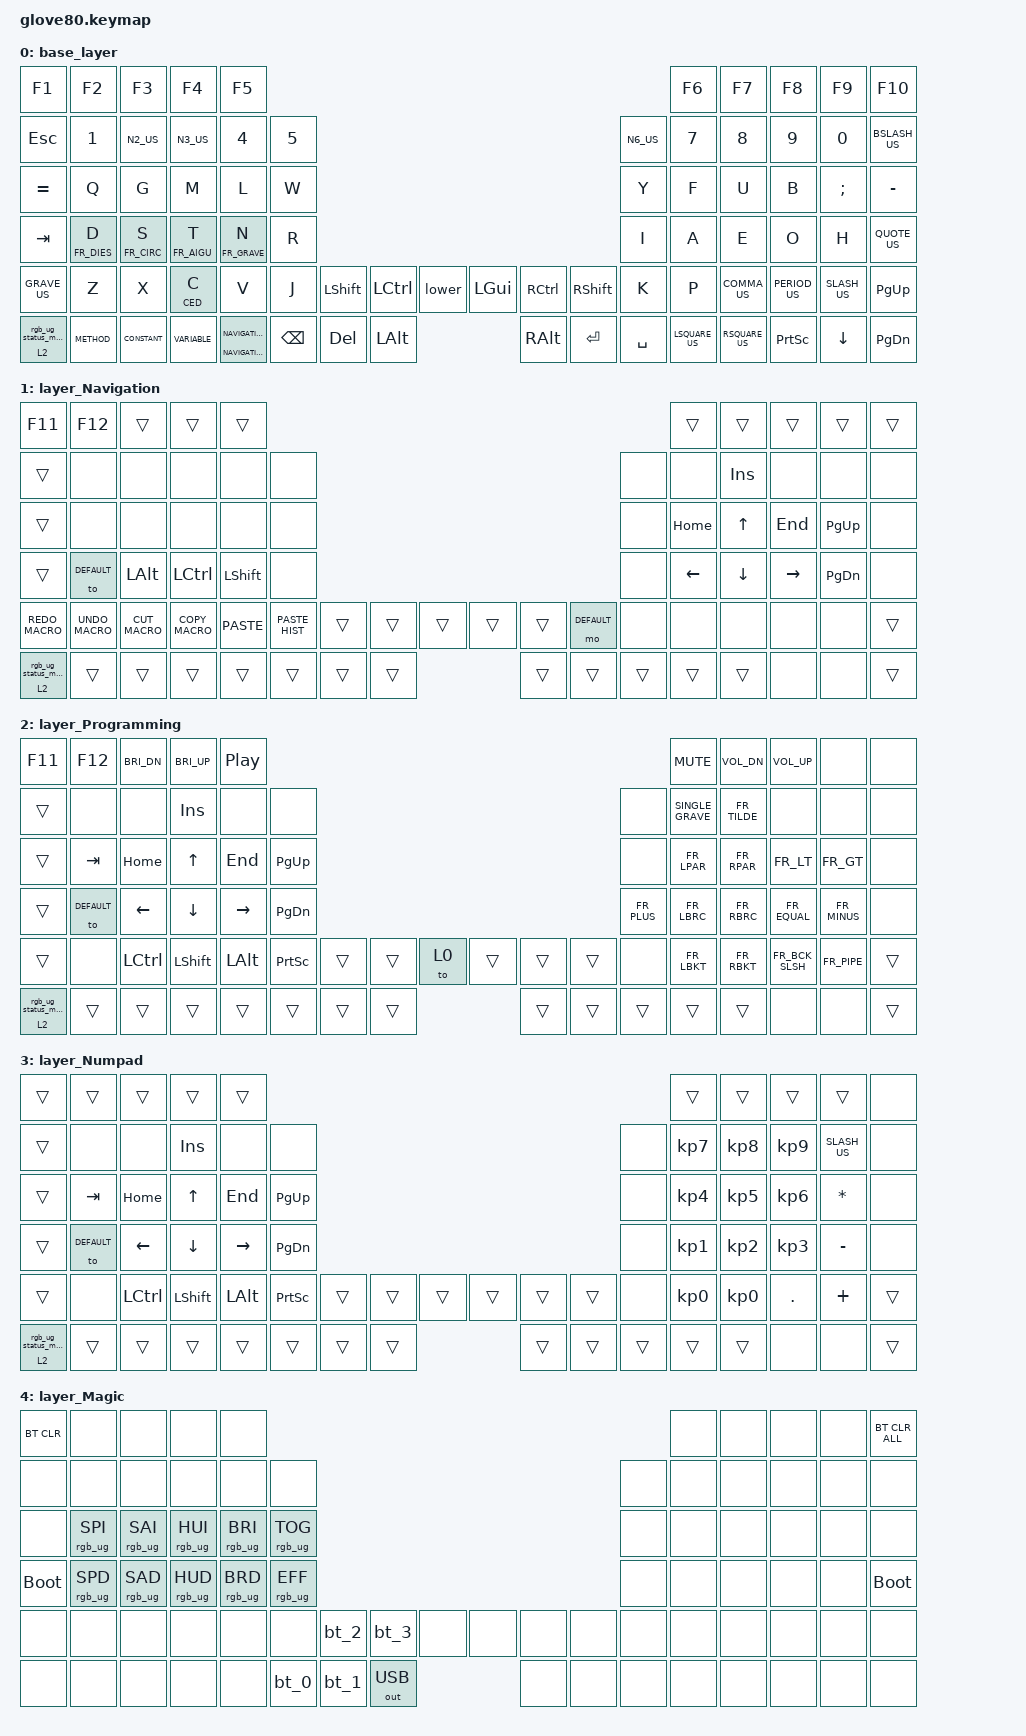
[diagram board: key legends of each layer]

/*
 * Copyright (c) 2020 The ZMK Contributors
 * Copyright (c) 2022 Innaworks Development Limited, trading as MoErgo
 *
 * SPDX-License-Identifier: MIT
 */


/* THIS FILE WAS GENERATED BY GLOVE80 LAYOUT EDITOR
 *
 * This file was generated automatically. You may or may not want to
 * edit it directly.
 */

#include <behaviors.dtsi>
/* Include all behaviour includes needed by system behaviors/macros */
#include <dt-bindings/zmk/outputs.h>

/* Include behaviour includes needed by key binds - automatically generated */
#include <dt-bindings/zmk/keys.h>
#include <dt-bindings/zmk/bt.h>
#include <dt-bindings/zmk/rgb.h>
#include <dt-bindings/zmk/outputs.h>
#include <dt-bindings/zmk/keyboards/keys_fr_cafr.h>

#define DEFAULT  0
#define NAVIGATION   1
#define SYMBOL   2
#define NUMPAD  3

#define VOWEL_A 42
#define VOWEL_E 43
#define VOWEL_I 41
#define VOWEL_O 44
#define VOWEL_U 31
#define AIGU_VOWELS VOWEL_E
#define GRAVE_VOWELS VOWEL_A VOWEL_E VOWEL_U
#define CIRC_VOWELS VOWEL_A VOWEL_E VOWEL_I VOWEL_O VOWEL_U
#define TREMA_VOWELS VOWEL_E VOWEL_I VOWEL_U


/ {
    /* Glove80 system behavior & macros */
    behaviors {
        // For the "layer" key, it'd nice to be able to use it as either a shift or a toggle.
        // Configure it as a tap dance, so the first tap (or hold) is a &mo and the second tap is a &to
        lower: tap_dance_0 {
            compatible = "zmk,behavior-tap-dance";
            label = "LAYER_TAP_DANCE";
            #binding-cells = <0>;
            tapping-term-ms = <200>;
            bindings = <&mo 1>, <&to 1>;
        };

        GRAVE_US: GRAVE_US {
            compatible = "zmk,behavior-mod-morph";
            label = "GRAVE_US";
            #binding-cells = <0>;
            bindings = <&SINGLE_GRAVE>, <&kp FR_TILDE>;
            mods = <(MOD_LSFT|MOD_RSFT)>;
        };

        N2_US: N2_US {
            compatible = "zmk,behavior-mod-morph";
            label = "N2_US";
            #binding-cells = <0>;
            bindings = <&kp N2>, <&kp FR_AT>;
            mods = <(MOD_LSFT|MOD_RSFT)>;
        };

        N3_US: N3_US {
            compatible = "zmk,behavior-mod-morph";
            label = "N3_US";
            #binding-cells = <0>;
            bindings = <&kp N3>, <&kp FR_HASH>;
            mods = <(MOD_LSFT|MOD_RSFT)>;
        };

        N6_US: N6_US {
            compatible = "zmk,behavior-mod-morph";
            label = "N6_US";
            #binding-cells = <0>;
            bindings = <&kp N6>, <&SINGLE_KARET>;
            mods = <(MOD_LSFT|MOD_RSFT)>;
        };

        LSQUARE_US: LSQUARE_US {
            compatible = "zmk,behavior-mod-morph";
            label = "LSQUARE_US";
            #binding-cells = <0>;
            bindings = <&kp FR_LBKT>, <&kp FR_LBRC>;
            mods = <(MOD_LSFT|MOD_RSFT)>;
        };

        RSQUARE_US: RSQUARE_US {
            compatible = "zmk,behavior-mod-morph";
            label = "RSQUARE_US";
            #binding-cells = <0>;
            bindings = <&kp FR_RBKT>, <&kp FR_RBRC>;
            mods = <(MOD_LSFT|MOD_RSFT)>;
        };

        BSLASH_US: BSLASH_US {
            compatible = "zmk,behavior-mod-morph";
            label = "BSLASH_US";
            #binding-cells = <0>;
            bindings = <&kp FR_BCK_SLSH>, <&kp FR_PIPE>;
            mods = <(MOD_LSFT|MOD_RSFT)>;
        };

        QUOTE_US: QUOTE_US {
            compatible = "zmk,behavior-mod-morph";
            label = "QUOTE_US";
            #binding-cells = <0>;
            bindings = <&kp FR_SINGLE_QUOTE>, <&kp FR_QUOTE>;
            mods = <(MOD_LSFT|MOD_RSFT)>;
        };

        COMMA_US: COMMA_US {
            compatible = "zmk,behavior-mod-morph";
            label = "COMMA_US";
            #binding-cells = <0>;
            bindings = <&kp FR_COMMA>, <&kp FR_LT>;
            mods = <(MOD_LSFT|MOD_RSFT)>;
        };

        PERIOD_US: PERIOD_US {
            compatible = "zmk,behavior-mod-morph";
            label = "PERIOD_US";
            #binding-cells = <0>;
            bindings = <&kp FR_DOT>, <&kp FR_GT>;
            mods = <(MOD_LSFT|MOD_RSFT)>;
        };

        SLASH_US: SLASH_US {
            compatible = "zmk,behavior-mod-morph";
            label = "SLASH_US";
            #binding-cells = <0>;
            bindings = <&kp FR_SLASH>, <&kp FR_QUES>;
            mods = <(MOD_LSFT|MOD_RSFT)>;
        };

        ACC_1: ACC_1 {
            compatible = "zmk,behavior-hold-tap";
            label = "ACCENT_1";
            #binding-cells = <2>;
            flavor = "balanced";
            tapping-term-ms = <175>;
            quick-tap-ms = <150>;
            global-quick-tap-ms = <150>;
            bindings = <&kp>, <&kp>;
            hold-trigger-key-positions = <GRAVE_VOWELS>;
            hold-trigger-on-release;
        };

        ACC_2: ACC_2 {
            compatible = "zmk,behavior-hold-tap";
            label = "ACCENT_2";
            #binding-cells = <2>;
            flavor = "balanced";
            tapping-term-ms = <175>;
            quick-tap-ms = <150>;
            global-quick-tap-ms = <150>;
            bindings = <&kp>, <&kp>;
            hold-trigger-key-positions = <AIGU_VOWELS>;
            hold-trigger-on-release;
        };

        ACC_3: ACC_3 {
            compatible = "zmk,behavior-hold-tap";
            label = "ACCENT_3";
            #binding-cells = <2>;
            flavor = "balanced";
            tapping-term-ms = <175>;
            quick-tap-ms = <150>;
            global-quick-tap-ms = <150>;
            bindings = <&kp>, <&kp>;
            hold-trigger-key-positions = <CIRC_VOWELS>;
            hold-trigger-on-release;
        };

        ACC_4: ACC_4 {
            compatible = "zmk,behavior-hold-tap";
            label = "ACCENT_4";
            #binding-cells = <2>;
            flavor = "balanced";
            tapping-term-ms = <175>;
            quick-tap-ms = <150>;
            global-quick-tap-ms = <150>;
            bindings = <&kp>, <&kp>;
            hold-trigger-key-positions = <TREMA_VOWELS>;
            hold-trigger-on-release;
        };

        TO_OR_MO: TO_OR_MO {
            compatible = "zmk,behavior-hold-tap";
            label = "TO_OR_MO";
            #binding-cells = <2>;
            flavor = "balanced";
            tapping-term-ms = <300>;
            bindings = <&mo>, <&to>;
            hold-trigger-on-release;
        };

        CED: CED {
            compatible = "zmk,behavior-hold-tap";
            label = "CED";
            #binding-cells = <2>;
            flavor = "balanced";
            tapping-term-ms = <175>;
            quick-tap-ms = <150>;
            global-quick-tap-ms = <150>;
            bindings = <&CAPITAL_CED_OR_NOT>, <&kp>;
            hold-trigger-key-positions = <49>;
            hold-trigger-on-release;
        };

        CAPITAL_CED_OR_NOT: CAPITAL_CED_OR_NOT {
            compatible = "zmk,behavior-mod-morph";
            label = "CAPITAL_CED_OR_NOT";
            #binding-cells = <0>;
            bindings = <&C_CEDILLE>, <&CAPITAL_C_CEDILLE>;
            mods = <(MOD_LSFT|MOD_RSFT)>;
        };
    };


    macros {
        rgb_ug_status_macro: rgb_ug_status_macro_0 {
            label = "RGB_UG_STATUS";
            compatible = "zmk,behavior-macro";
            #binding-cells = <0>;
            bindings
                = <&rgb_ug RGB_STATUS>;
        };

        SINGLE_KARET: SINGLE_KARET {
            label = "SINGLE_KARET";
            compatible = "zmk,behavior-macro";
            #binding-cells = <0>;
            wait-ms = <0>;
            tap-ms = <0>;
            bindings = <&macro_tap &kp FR_CIRC &kp FR_CIRC &kp BSPC>;
        };

        SINGLE_GRAVE: SINGLE_GRAVE {
            label = "SINGLE_GRAVE";
            compatible = "zmk,behavior-macro";
            #binding-cells = <0>;
            wait-ms = <0>;
            tap-ms = <0>;
            bindings = <&macro_tap &kp FR_GRAVE &kp FR_GRAVE &kp BSPC>;
        };

        C_CEDILLE: C_CEDILLE {
            label = "C_CEDILLE";
            compatible = "zmk,behavior-macro";
            #binding-cells = <0>;
            wait-ms = <0>;
            tap-ms = <0>;
            bindings = <&macro_tap &kp FR_CED &kp C>;
        };

        CAPITAL_C_CEDILLE: CAPITAL_C_CEDILLE {
            label = "CAPITAL_C_CEDILLE";
            compatible = "zmk,behavior-macro";
            #binding-cells = <0>;
            wait-ms = <0>;
            tap-ms = <0>;
            bindings =
                <&macro_tap &kp FR_CED>,
                <&macro_press &kp LSHFT>,
                <&macro_tap &kp C>,
                <&macro_release &kp LSHFT>;
        };

        COPY_MACRO: COPY_MACRO {
            label = "COPY_MACRO";
            compatible = "zmk,behavior-macro";
            #binding-cells = <0>;
            wait-ms = <0>;
            tap-ms = <0>;
            bindings =
                <&macro_press &kp LCTRL>,
                <&macro_tap &kp C>,
                <&macro_release &kp LCTRL>;
        };

        PASTE: PASTE {
            label = "PASTE";
            compatible = "zmk,behavior-macro";
            #binding-cells = <0>;
            wait-ms = <0>;
            tap-ms = <0>;
            bindings =
                <&macro_press &kp LCTRL>,
                <&macro_tap &kp V>,
                <&macro_release &kp LCTRL>;
        };

        CUT_MACRO: CUT_MACRO {
            label = "CUT_MACRO";
            compatible = "zmk,behavior-macro";
            #binding-cells = <0>;
            wait-ms = <0>;
            tap-ms = <0>;
            bindings =
                <&macro_press &kp LCTRL>,
                <&macro_tap &kp X>,
                <&macro_release &kp LCTRL>;
        };

        UNDO_MACRO: UNDO_MACRO {
            label = "UNDO_MACRO";
            compatible = "zmk,behavior-macro";
            #binding-cells = <0>;
            wait-ms = <0>;
            tap-ms = <0>;
            bindings =
                <&macro_press &kp LCTRL>,
                <&macro_tap &kp Z>,
                <&macro_release &kp LCTRL>;
        };

        REDO_MACRO: REDO_MACRO {
            label = "REDO_MACRO";
            compatible = "zmk,behavior-macro";
            #binding-cells = <0>;
            wait-ms = <0>;
            tap-ms = <0>;
            bindings =
                <&macro_press &kp LCTRL>,
                <&macro_press &kp LSHFT>,
                <&macro_tap &kp Z>,
                <&macro_release &kp LCTRL>,
                <&macro_release &kp LSHFT>;
        };

        PASTE_HIST: PASTE_HIST {
            label = "PASTE_HIST";
            compatible = "zmk,behavior-macro";
            #binding-cells = <0>;
            wait-ms = <0>;
            tap-ms = <0>;
            bindings =
                <&macro_press &kp LCTRL>,
                <&macro_press &kp LSHFT>,
                <&macro_tap &kp V>,
                <&macro_release &kp LCTRL>,
                <&macro_release &kp LSHFT>;
        };

        VARIABLE: VARIABLE {
            label = "VARIABLE";
            compatible = "zmk,behavior-macro";
            #binding-cells = <0>;
            wait-ms = <0>;
            tap-ms = <0>;
            bindings =
                <&macro_press &kp LCTRL>,
                <&macro_press &kp LALT>,
                <&macro_tap &kp V>,
                <&macro_release &kp LCTRL>,
                <&macro_release &kp LALT>;
        };

        CONSTANT: CONSTANT {
            label = "CONSTANT";
            compatible = "zmk,behavior-macro";
            #binding-cells = <0>;
            wait-ms = <0>;
            tap-ms = <0>;
            bindings =
                <&macro_press &kp LCTRL>,
                <&macro_press &kp LALT>,
                <&macro_tap &kp C>,
                <&macro_release &kp LCTRL>,
                <&macro_release &kp LALT>;
        };

        METHOD: METHOD {
            label = "METHOD";
            compatible = "zmk,behavior-macro";
            #binding-cells = <0>;
            wait-ms = <0>;
            tap-ms = <0>;
            bindings =
                <&macro_press &kp LCTRL>,
                <&macro_press &kp LALT>,
                <&macro_tap &kp M>,
                <&macro_release &kp LCTRL>,
                <&macro_release &kp LALT>;
        };

        bt_0: bt_profile_macro_0 {
            label = "BT_0";
            compatible = "zmk,behavior-macro";
            #binding-cells = <0>;
            bindings
                = <&out OUT_BLE>,
                  <&bt BT_SEL 0>;
        };

        bt_1: bt_profile_macro_1 {
            label = "BT_1";
            compatible = "zmk,behavior-macro";
            #binding-cells = <0>;
            bindings
                = <&out OUT_BLE>,
                  <&bt BT_SEL 1>;
        };

        bt_2: bt_profile_macro_2 {
            label = "BT_2";
            compatible = "zmk,behavior-macro";
            #binding-cells = <0>;
            bindings
                = <&out OUT_BLE>,
                  <&bt BT_SEL 2>;
        };

        bt_3: bt_profile_macro_3 {
            label = "BT_3";
            compatible = "zmk,behavior-macro";
            #binding-cells = <0>;
            bindings
                = <&out OUT_BLE>,
                  <&bt BT_SEL 3>;
        };
    };

    magic: magic_hold_tap {
        compatible = "zmk,behavior-hold-tap";
        label = "MAGIC_HOLD_TAP";
        #binding-cells = <2>;
        flavor = "tap-preferred";
        tapping-term-ms = <200>;
        bindings = <&mo>, <&rgb_ug_status_macro>;
    };

    /* Custom Defined Behaviors */


    /* Automatically generated keymap */
    keymap {
        compatible = "zmk,keymap";


        base_layer {
            bindings = <
     &kp F1    &kp F2             &kp F3              &kp F4                    &kp F5                                                                                     &kp F6  &kp F7       &kp F8       &kp F9      &kp F10
    &kp ESC    &kp N1             &N2_US              &N3_US                    &kp N4                         &kp N5                                                                  &N6_US  &kp N7       &kp N8       &kp N9       &kp N0   &BSLASH_US
  &kp EQUAL     &kp Q              &kp G               &kp M                     &kp L                          &kp W                                                                   &kp Y   &kp F        &kp U        &kp B     &kp SEMI    &kp MINUS
    &kp TAB    &ACC_4 FR_DIES D   &ACC_3 FR_CIRC S    &ACC_2 FR_AIGU T          &ACC_1 FR_GRAVE N               &kp R                                                                   &kp I   &kp A        &kp E        &kp O        &kp H    &QUOTE_US
  &GRAVE_US     &kp Z              &kp X                &CED C            &kp V                          &kp J  &kp LSHFT  &kp LCTRL    &lower  &kp LGUI  &kp RCTRL  &kp RSHFT   &kp K   &kp P    &COMMA_US   &PERIOD_US    &SLASH_US    &kp PG_UP
 &magic 2 0   &METHOD          &CONSTANT           &VARIABLE                 &TO_OR_MO NAVIGATION NAVIGATION            &kp BSPC    &kp DEL  &kp LALT  &kp RALT    &kp RET  &kp SPACE     &LSQUARE_US  &RSQUARE_US    &kp PSCRN     &kp DOWN    &kp PG_DN
            >;
        };

        layer_Navigation {
            bindings = <
    &kp F11      &kp F12      &trans       &trans     &trans                                                                               &trans     &trans     &trans      &trans  &trans
     &trans        &none       &none        &none      &none        &none                                                        &none      &none    &kp INS      &none       &none   &none
     &trans      &none         &none        &none      &none        &none                                                        &none   &kp HOME     &kp UP    &kp END   &kp PG_UP   &none
     &trans  &to DEFAULT    &kp LALT    &kp LCTRL  &kp LSHFT        &none                                                        &none   &kp LEFT   &kp DOWN  &kp RIGHT   &kp PG_DN   &none
&REDO_MACRO  &UNDO_MACRO  &CUT_MACRO  &COPY_MACRO     &PASTE  &PASTE_HIST  &trans  &trans  &trans  &trans  &trans  &mo DEFAULT   &none      &none      &none      &none       &none  &trans
 &magic 2 0       &trans      &trans       &trans     &trans               &trans  &trans  &trans  &trans  &trans  &trans       &trans     &trans      &none      &none      &trans
            >;
        };

        layer_Programming {
            bindings = <
    &kp F11      &kp F12    &kp C_BRI_DN    &kp C_BRI_UP         &kp C_PP                                                                                 &kp C_MUTE     &kp C_VOL_DN     &kp C_VOL_UP         &none   &none
     &trans        &none           &none         &kp INS            &none      &none                                                         &none     &SINGLE_GRAVE     &kp FR_TILDE            &none         &none   &none
     &trans      &kp TAB        &kp HOME    &kp UP_ARROW          &kp END  &kp PG_UP                                                         &none       &kp FR_LPAR      &kp FR_RPAR        &kp FR_LT     &kp FR_GT   &none
     &trans  &to DEFAULT  &kp LEFT_ARROW  &kp DOWN_ARROW  &kp RIGHT_ARROW  &kp PG_DN                                                   &kp FR_PLUS       &kp FR_LBRC      &kp FR_RBRC     &kp FR_EQUAL  &kp FR_MINUS   &none
     &trans        &none       &kp LCTRL       &kp LSHFT         &kp LALT  &kp PSCRN  &trans  &trans   &to 0  &trans  &trans  &trans         &none       &kp FR_LBKT      &kp FR_RBKT  &kp FR_BCK_SLSH   &kp FR_PIPE  &trans
 &magic 2 0       &trans          &trans          &trans           &trans             &trans  &trans  &trans  &trans  &trans  &trans                          &trans           &trans            &none         &none  &trans
            >;
        };

        layer_Numpad {
            bindings = <
     &trans       &trans     &trans     &trans     &trans                                                                        &trans     &trans     &trans     &trans   &none
     &trans        &none      &none    &kp INS      &none      &none                                                   &none  &kp KP_N7  &kp KP_N8  &kp KP_N9  &SLASH_US   &none
     &trans      &kp TAB   &kp HOME     &kp UP    &kp END  &kp PG_UP                                                   &none  &kp KP_N4  &kp KP_N5  &kp KP_N6   &kp STAR   &none
     &trans  &to DEFAULT   &kp LEFT   &kp DOWN  &kp RIGHT  &kp PG_DN                                                   &none  &kp KP_N1  &kp KP_N2  &kp KP_N3  &kp MINUS   &none
     &trans        &none  &kp LCTRL  &kp LSHFT   &kp LALT  &kp PSCRN  &trans  &trans  &trans  &trans  &trans  &trans   &none  &kp KP_N0  &kp KP_N0    &kp DOT   &kp PLUS  &trans
 &magic 2 0       &trans     &trans     &trans     &trans             &trans  &trans  &trans  &trans  &trans  &trans             &trans     &trans      &none      &none  &trans
            >;
        };

        layer_Magic {
            bindings = <
  &bt BT_CLR            &none            &none            &none            &none                                                                                  &none   &none   &none   &none  &bt BT_CLR_ALL
       &none            &none            &none            &none            &none            &none                                                         &none   &none   &none   &none   &none           &none
       &none  &rgb_ug RGB_SPI  &rgb_ug RGB_SAI  &rgb_ug RGB_HUI  &rgb_ug RGB_BRI  &rgb_ug RGB_TOG                                                         &none   &none   &none   &none   &none           &none
 &bootloader  &rgb_ug RGB_SPD  &rgb_ug RGB_SAD  &rgb_ug RGB_HUD  &rgb_ug RGB_BRD  &rgb_ug RGB_EFF                                                         &none   &none   &none   &none   &none     &bootloader
       &none            &none            &none            &none            &none            &none   &bt_2   &bt_3         &none   &none   &none   &none   &none   &none   &none   &none   &none           &none
       &none            &none            &none            &none            &none                    &bt_0   &bt_1  &out OUT_USB   &none   &none   &none           &none   &none   &none   &none           &none
            >;
        };

    };
};
